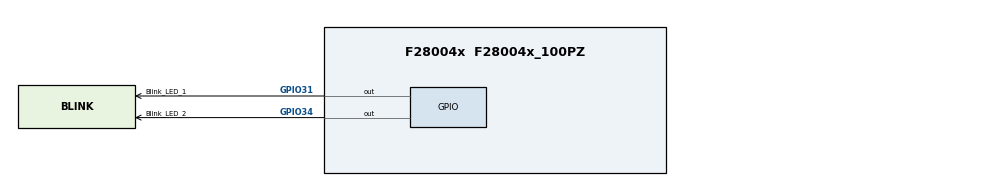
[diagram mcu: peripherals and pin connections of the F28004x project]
/**
 * @cliArgs --device "F28004x" --part "F28004x_100PZ" --package "F28004x_100PZ" --product "C2000WARE@4.01.00.00"
 * @versions {"tool":"1.22.0+3893"}
 */

/**
 * Import the modules used in this configuration.
 */
const adc       = scripting.addModule("/driverlib/adc.js", {}, false);
const adc1      = adc.addInstance();
const cputimer  = scripting.addModule("/driverlib/cputimer.js", {}, false);
const cputimer1 = cputimer.addInstance();
const epwm      = scripting.addModule("/driverlib/epwm.js", {}, false);
const epwm1     = epwm.addInstance();
const epwm2     = epwm.addInstance();
const gpio      = scripting.addModule("/driverlib/gpio.js", {}, false);
const gpio1     = gpio.addInstance();
const gpio2     = gpio.addInstance();

/**
 * Write custom configuration values to the imported modules.
 */
adc1.$name       = "myADC0";
adc1.enabledSOCs = ["ADC_SOC_NUMBER0"];
adc1.soc0Trigger = "ADC_TRIGGER_EPWM1_SOCA";

cputimer1.$name                    = "Led_Toggle_Timer";
cputimer1.enableInterrupt          = true;
cputimer1.registerInterrupts       = true;
cputimer1.startTimer               = true;
cputimer1.timerPeriod              = 100000000;
cputimer1.timerInt.enableInterrupt = true;

epwm1.$name                   = "myEPWM0";
epwm1.epwmTimebase_period     = 0.00001;
epwm1.epwmTimebase_periodLink = "EPWM_LINK_WITH_EPWM_1";

epwm2.$name = "myEPWM1";

gpio1.$name             = "Blink_LED_1";
gpio1.direction         = "GPIO_DIR_MODE_OUT";
gpio1.writeInitialValue = true;
gpio1.gpioPin.$assign   = "GPIO31";

gpio2.$name             = "Blink_LED_2";
gpio2.direction         = "GPIO_DIR_MODE_OUT";
gpio2.writeInitialValue = true;
gpio2.gpioPin.$assign   = "GPIO34";

/**
 * Pinmux solution for unlocked pins/peripherals. This ensures that minor changes to the automatic solver in a future
 * version of the tool will not impact the pinmux you originally saw.  These lines can be completely deleted in order to
 * re-solve from scratch.
 */
epwm1.epwm.$suggestSolution           = "EPWM2";
epwm1.epwm.epwm_aPin.$suggestSolution = "GPIO2";
epwm1.epwm.epwm_bPin.$suggestSolution = "GPIO3";
epwm2.epwm.$suggestSolution           = "EPWM1";
epwm2.epwm.epwm_aPin.$suggestSolution = "GPIO0";
epwm2.epwm.epwm_bPin.$suggestSolution = "GPIO1";
